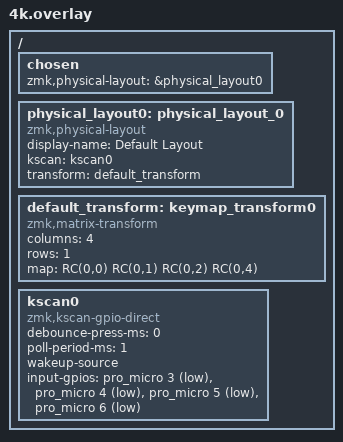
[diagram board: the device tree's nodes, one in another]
#include <dt-bindings/zmk/matrix_transform.h>

/ {
    chosen {
        zmk,physical-layout = &physical_layout0;
    };

    physical_layout0: physical_layout_0 {
        compatible = "zmk,physical-layout";
        display-name = "Default Layout";
        kscan = <&kscan0>;
        transform = <&default_transform>;
    };

    default_transform: keymap_transform0 {
        compatible = "zmk,matrix-transform";
        columns = <4>;
        rows = <1>;
        map = <
            RC(0,0) RC(0,1) RC(0,2) RC(0,4)
        >;
    };

    kscan0: kscan0 {
        compatible = "zmk,kscan-gpio-direct";
        debounce-press-ms = 0;
        poll-period-ms = 1;
        wakeup-source;

        input-gpios
            = <&pro_micro 3 (GPIO_ACTIVE_LOW | GPIO_PULL_UP)>
            , <&pro_micro 4 (GPIO_ACTIVE_LOW | GPIO_PULL_UP)>
            , <&pro_micro 5 (GPIO_ACTIVE_LOW | GPIO_PULL_UP)>
            , <&pro_micro 6 (GPIO_ACTIVE_LOW | GPIO_PULL_UP)>
            ;
    };
};
